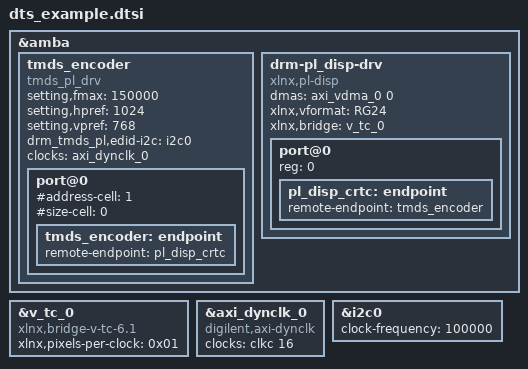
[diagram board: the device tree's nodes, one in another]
/include/ "system-conf.dtsi"

&amba { 
    tmds_encoder { 
        compatible = "tmds_pl_drv"; 
        setting,fmax = <150000>;
        setting,hpref = <1024>;                     // Preferred horizontal size
        setting,vpref = <768>;                      // Preferred vertical size
        drm_tmds_pl,edid-i2c = <&i2c0>;             // EDID I2C phandle, remember to set the freq below
		clocks = <&axi_dynclk_0>;                   // Dynamic clock phandle
		clock-names = "clk";
        port@0{
			#address-cell = <1>; 
        	#size-cell = <0>; 
            tmds_encoder: endpoint{
                remote-endpoint = <&pl_disp_crtc>;
            };
        };
    };

    drm-pl_disp-drv {
        compatible = "xlnx,pl-disp";
        dmas = <&axi_vdma_0 0>;                     // Video DMA phandle
        dma-names = "dma0";
        xlnx,vformat = "RG24";
        xlnx,bridge = <&v_tc_0>;                    // Video timming controller phandle 
        port@0{
            reg = <0>;
            pl_disp_crtc: endpoint{
                remote-endpoint = <&tmds_encoder>;
            };
        };
    }; 
};

&v_tc_0 {
    compatible = "xlnx,bridge-v-tc-6.1";            // Edit according to /drivers/gpu/drm/xlnx/xlnx_vtc.c
    xlnx,pixels-per-clock = <0x01>; 
};

&axi_dynclk_0 {
	compatible = "digilent,axi-dynclk";
	#clock-cells = <0>;
	clocks = <&clkc 16>;                            // 100MHz ref clock phandle (LIKELY TO BE CHANGED)
};

&i2c0 {
	clock-frequency = <100000>;                     // EDID I2C freq
};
